# C7X256V_DEBUG_COLUMBO_COLUMBO_REG_000734001000h register map
Vendor: Texas Instruments
Peripheral module from a debugger description file (folder am62D).
Registers are 32-bit, access per field, reset values left out (the file's numbers can be read two ways) unless marked. A register's access mark holds for its fields unless they carry their own. Offsets are as the file gives them; lines under a group give offsets from that group; [hi:lo] are bit positions; {n}, {i} and the like mark numbered series; 'fields as' and 'values as' point back to an identical list; <NAME> marks a mode.

## columbo_columbo_reg
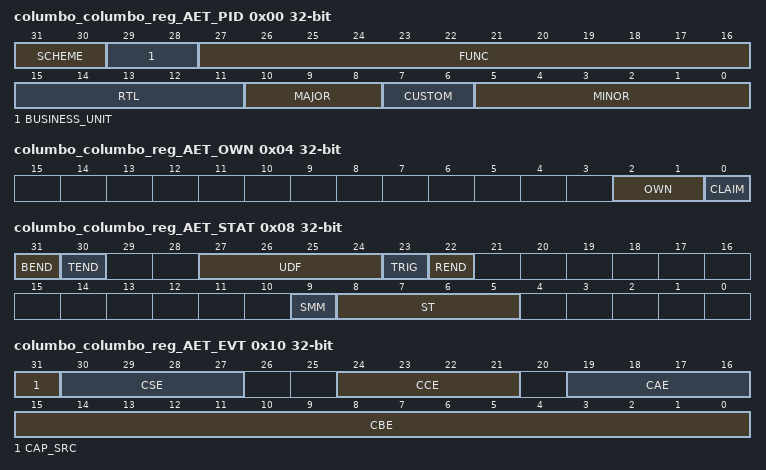
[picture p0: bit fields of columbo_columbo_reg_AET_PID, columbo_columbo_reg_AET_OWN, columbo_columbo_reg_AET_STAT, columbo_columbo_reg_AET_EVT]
0x00 columbo_columbo_reg_AET_PID — This register is used to identify this implementation of AET
  [31:30] SCHEME ro — Defines the scheme Reads return 01b
  [29:28] BUSINESS_UNIT ro — Business Unit Reads return 10b
  [27:16] FUNC ro — Functional Group 0x200 is reserved for AET
  [15:11] RTL ro — RTL Revision This value is implementation defined
  [10:8] MAJOR ro — Major Revision
  [7:6] CUSTOM rw — Custom Field Reads return 0x0
  [5:0] MINOR ro — Minor Revision Reads return 0x0
0x04 columbo_columbo_reg_AET_OWN — Ownership Control and Status Register
  [2:1] OWN ro — The Ownership State
  [0] CLAIM rw — This bit is used to obtain exclusive ownership of the debug module for either the debug initiator or the application initiator Reads will always return 0 If the current state is NOT_OWNED o A debugger-initiated write of 1 will claim the module for use by the debugger initiator o An application-initiated write of 1 will claim the module for use by the application initiator If the current state is DBG_OWNED o A debugger-initiated write of 0 will release ownership o A debugger-initiated write of 1 has no effect o Application writes have no effect If the current state is APP_OWNED o An application-initiated write of 0 will release ownership o A debugger-initiated write of 0 will release ownership o A write of 1 has not effect
0x08 columbo_columbo_reg_AET_STAT — AET Status Register This register provides access to AET Status
  [31] BEND ro — A status bit set to a one by a qualified version of trigger that stops the CPU [qualified by FUNC_CNTL:BPE, FUNC_CNTL:BPC, and CPU State] Reset to a zero by Writing a one to IAR_ADD:RBEND A simultaneous set and reset condition causes the bit to be set Read 0: Indicates that a breakpoint trigger has not been generated recently Read 1: Indicates that a breakpoint trigger was recently encountered
  [30] TEND ro — Trace End Status A status bit set to a one by the trace end trigger Reset to a zero by a Writing a one to IAR_ADD:RTEND A simultaneous set and reset condition causes the bit to be set Read 0: Indicates that a trace end trigger has not been generated recently Read 1: Indicates that a trace end trigger was recently encountered
  [27:24] UDF ro — Counter Underflow Status The meaning of this field depend on the counter operating mode Generic Operating Mode This flag is set to a one when the counter specified by the index n is directed to count past zero to the maximum counter value Reset to a zero by Writing a one to IAR_ADD:RUDF[n] or by disabling the counter A simultaneous set and reset condition causes this bit to be set Watermark Operating Mode The UDF[n] flag is set to a one when the counter specified by the index n is directed to count past zero to the maximum counter value Reset to a zero by Writing a one to IAR_ADD:RUDF[n] or by disabling the counter A simultaneous set and reset condition causes this bit to be set The UDF[n+1] flag is set to a one when a watermark window is terminated [eg end trigger is acted on] Reset to a zero by a Writing a one to IAR_ADD:RUDF[n+1] or by disabling the counter A simultaneous set and reset condition causes this bit to be set
  [23] TRIG ro — Trace Trigger A status bit set to one by the trace trigger Reset to a zero by Writing a one to IAR_ADD:RTEND A simultaneous set and reset condition causes this bit to be set
  [22] REND ro — AET Interrupt Status A status bit set to a one by a qualified version of the CPU_INT trigger [qualified by FUNC_CNTL:RIE, FUNC_CNTL:RIC, and CPU State] Reset to a zero by Writing a one to IAR_ADD:RREND A simultaneous set and reset condition causes this bit to be set
  [9] SMM ro — State Machine Mode This bit shadows the FUNC_CNTL:SMM bit-field
  [8:5] ST ro — State Machine Current State SMM ST Encoding - 0000 State Machine not enabled 0 0001 State 0 0 0010 State 1 0 0100 State 2 0 1000 State 3 1 --01 State 0 [Machine 0] 1 --10 State 1 [Machine 0] 1 01-- State 0 [Machine 1] 1 10-- State 1 [Machine 1]
0x10 columbo_columbo_reg_AET_EVT — AET Event Register This register exposes the state of various internal AET events.
  [31] CAP_SRC rw — AET_EVT Capture Source This bitfield defines the behavior of the AET_EVT:CSE, AET_EVT:CCE, AET_EVT:CAE, and AET_PC registers 0: The AET_EVT Read Register will be frozen on BEND [CPU halt trigger event] 1: The AET_EVT Read Register will be frozen on REND [CPU_INT trigger event] Software shall only change CAP_SRC while BEND=0 and REND=0 Changing CAP_SRC at any other time will result in undefined behavior
  [30:27] CSE ro — Captured State Events The state events recorded are the events that existed when the CAP_SRC programmed trigger event was created This register is loaded continuously when the trigger event is in the inactive state ---0b : State Event S0 is inactive ---1b : State Event S0 is active --0-b : State Event S1 is inactive --1-b : State Event S1 is active -0--b : State Event S2 is inactive -1--b : State Event S2 is active 0---b : State Event S3 is inactive 1---b : State Event S3 is active
  [24:21] CCE ro — Captured Counter Events The counter events recorded are the events that existed when the CAP_SRC programmed trigger event was created This register is loaded continuously when the trigger event is in the inactive state 0-00b : Watermark Instance 0 Counter Event is inactive 0-01b : Watermark Instance 0 Counter Event is active --1-b : Reserved for future use 000-b : Watermark Instance 1 Counter Event is inactive 010-b : Watermark Instance 1 Counter Event is active 1---b : Reserved for future use
  [19:16] CAE ro — Captured Auxiliary Events The auxiliarly events recorded are the events that existed when the CAP_SRC programmed trigger event was created This register is loaded continuously when the trigger event is in the inactive state CAE[n] = 0 : AUX_EVT[n] is inactive CAE[n] = 1 : AUX _EVT[n] is active
  [15:0] CBE ro — Captured Bus Events The counter events recorded are the events that existed when the CAP_SRC programmed trigger event was created This register is loaded continuously when the trigger event is in the inactive state CBE[n] = 0 : BUS_EVT[n] is inactive CBE[n] = 1 : BUS_EVT[n] is active
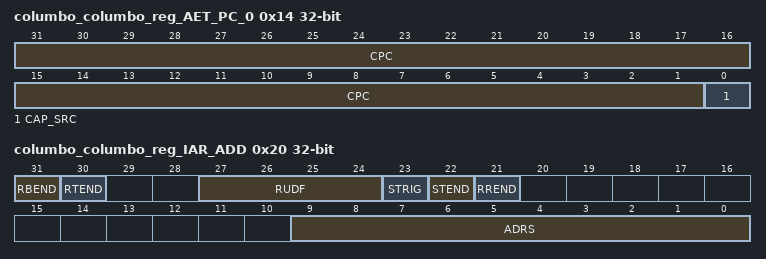
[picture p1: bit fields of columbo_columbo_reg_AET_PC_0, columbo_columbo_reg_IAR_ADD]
0x14 columbo_columbo_reg_AET_PC_0
  [31:1] CPC ro — Captured PC[31:01] The PC is recorded when the trigger event specified by AET_PC_0:CAP_SRC occurs The recorded PC is the state of the PC that caused or was present when the conditions were suitable for the trigger event to be set This register is loaded continuously when the trigger event is in the inactive state Software shall only change CAP_SRC while BEND=0 and REND=0 Changing CAP_SRC at any other time will result in undefined behavior
  [0] CAP_SRC rw — AET_PC Capture Source Write 0: The contents of AET_PC will be frozen on BEND [CPU_HALT trigger event] Write 1: The contents of AET_PC will be frozen on REND [CPU_INT trigger event]
0x18 columbo_columbo_reg_AET_PC_1 ro — AET PC Part 1 Read Register This register exposes bits 63-32 of the PC captured as a result of a trigger event specified in AET_PC_0:CAP_SRC.
  [31:0] CPC — Captured PC[63:32] The PC is recorded when the trigger event specified by AET_PC:CAP_SRC occurs The recorded PC is the state of the PC that caused or was present when the conditions were suitable for the trigger event to be set This register is loaded continuously when the trigger event is in the inactive state
0x20 columbo_columbo_reg_IAR_ADD rw — Captured PC[63:32] The PC is recorded when the trigger event specified by AET_PC:CAP_SRC occurs. The recorded PC is the state of the PC that caused or was present when the conditions were suitable for the trigger event to be set. This register is loaded continuously when the trigger event is in the inactive state.
  [31] RBEND — Reset Breakpoint End Status Software reset for AET_STAT:BEND status This bit has no memory so writes of 1 are self-clearing Reads : always return 0 Write 0 : No action Write 1 : Resets AET_STAT:BEND to a zero
  [30] RTEND — Reset Trace End Status Software reset for AET_STAT:TEND and AET_STAT:TRIG status This bit has no memory so writes of 1 are self-clearing Reads : always return 0 Write 0 : No action Write 1 : Resets AET_STAT:TEND and AET_STAT:TRIG to a zero
  [27:24] RUDF — Reset Counter Underflow Status Software reset for AET_STAT:UDF[n] status This bit has no memory so writes of 1 are self-clearing Reads : always return 0 Write 0 to bit n : No action Write 1 to bit n : Resets AET_STAT:UDF[n] to a zero
  [23] STRIG — Set Trace Trigger Software set for TRACE_TRIG trigger This bit has no memory so writes of 1 are self-clearing Reads : always return 0 Write 0 : No action Write 1 : Generates a TRACE_TRIG trigger
  [22] STEND — Set Trace End Software set for TRACE_END trigger This bit has no memory so writes of 1 are self-clearing Reads : always return 0 Write 0 : No action Write 1 : Generates a TRACE_END trigger
  [21] RREND — Reset AET Interrupt Status Software reset for AET_STAT:REND status This bit has no memory so writes of 1 are self-clearing Reads : always return 0 Write 0 : No action Write 1 : Resets AET_STAT:REND to a zero
  [9:0] ADRS — This 10-bit value creates the indirect register address
0x24 columbo_columbo_reg_IAR_DAT rw — IAR Data Register This register allows the reading and writing of indirect register values
  [31:0] DATA — Indirectly Addressable Read Register Data Reads : return the value of the register referenced by IAR_ADD:ADDRS[9:0] Writes : initialize the register referenced by IAR_ADD:ADDRS[9:0] with the value contained here
